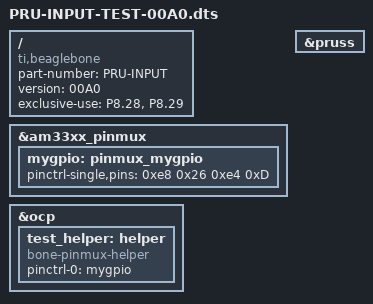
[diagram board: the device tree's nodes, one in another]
/*
       PRU-INPUT 
*/
/dts-v1/;
/plugin/;
 

/ {
  compatible = "ti,beaglebone", "ti,beaglebone-black";
 
  /* identification */
  part-number = "PRU-INPUT";
  version = "00A0";
  exclusive-use =
    "P8.28",
    "P8.29";
 
  fragment@0 {
    target = <&am33xx_pinmux>;
    __overlay__ {
      mygpio: pinmux_mygpio{
        pinctrl-single,pins = <
          0xe8 0x26
          0xe4 0xD
          >;
      };
    };
  };
 
  fragment@1 {
    target = <&ocp>;
    __overlay__ {
      test_helper: helper {
        compatible = "bone-pinmux-helper";
        pinctrl-names = "default";
        pinctrl-0 = <&mygpio>;
        status = "okay";
      };
    };
  };
 
  fragment@2{
  target = <&pruss>;
    __overlay__ {
      status = "okay";
    };
  };
};
